# CCG2 register map
File version: 1.0
CPU: CM0 r1p0, little endian, no MPU, no FPU, 2 interrupt priority bits
Registers are 32-bit, read-write, reset 0x0 unless marked. A register's access mark holds for its fields unless they carry their own. Offsets are from the block's base; [hi:lo] are bit positions; {n}, {i} and the like mark numbered series; 'fields as' and 'values as' point back to an identical list.

## PERI
Base 0x40010000
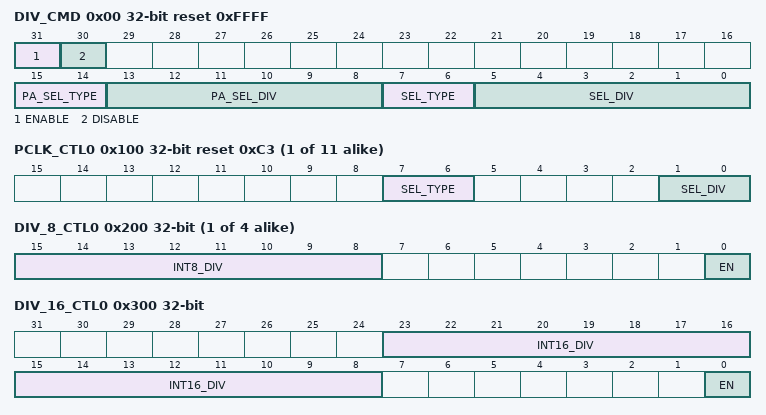
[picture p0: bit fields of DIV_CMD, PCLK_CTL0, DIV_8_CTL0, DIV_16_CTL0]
0x00 DIV_CMD reset 0xFFFF — Divider command register The (PA_SEL_TYPE, PA_SEL_DIV) field pair allows a divider to be phase aligned with another divider. E.g., consider a 48 MHz "clk_hf", and a need for a 12 MHz divided clock A and a 8 MHz divided clock B. Clock A uses 8.0 integer divider 0 and is created by aligning it to "clk_hf" ((PA_SEL_TYPE, PA_SEL_DIV) is (3, 63)) and DIV_8_CTL0.INT8_DIV is "4-1". Clock B uses 8.0 integer divider 1 and is created by aligning it to clock A ((PA_SEL_TYPE, PA_SEL_DIV) is (0, 0)) and DIV_8_CTL1.INT8_DIV is "6-1". This guarantees that clock B is phase aligned with clock B: as the smallest common multiple of the two clock periods is 12 "clk_hf" cycles, the clocks A and B will be aligned every 12 "clk_hf" cycles. Note: clock B is phase aligned to clock A, but still uses "clk_hf" as a reference clock for its divider value.
  [31] ENABLE — Clock divider enable command (mutually exclusive with DISABLE). Typically, SW sets this field to '1' to enable a divider and HW sets this field to '0' to indicate that divider enabling has completed. When a divider is enabled, its integer and fractional (if present) counters are initialized to "0". If a divider is to be re-enabled using different integer and fractional divider values, the SW should follow these steps: 0: Disable the divider using the DIV_CMD.DISABLE field. 1: Configure the divider's DIV_XXX_CTL register. 2: Enable the divider using the DIV_CMD_ENABLE field. The SEL_DIV and SEL_TYPE fields specify which divider is to be enabled. The enabled divider may be phase aligned to either "clk_hf" (typical usage) or to ANY enabled divider. The PA_SEL_DIV and P_SEL_TYPE fields specify the reference divider. The HW sets the ENABLE field to '0' when the enabling is performed and the HW set the DIV_XXX_CTL.EN field of the divider to '1' when the enabling is performed. Note that enabling with phase alignment to a low frequency divider takes time. E.g. To align to a divider that generates a clock of "clk_hf"/n (with n being the integer divider value INT_DIV+1), up to n cycles may be required to perform alignment. Phase alignment to "clk_hf" takes affect immediately. SW can set this field to '0' during phase alignment to abort the enabling process.
  [30] DISABLE — Clock divider disable command (mutually exlusive with ENABLE). SW sets this field to '1' and HW sets this field to '0'. The SEL_DIV and SEL_TYPE fields specify which divider is to be disabled. The HW sets the DISABLE field to '0' immediately and the HW sets the DIV_XXX_CTL.EN field of the divider to '0' immediately.
  [15:14] PA_SEL_TYPE — Specifies the divider type of the divider to which phase alignment is performed for the clock enable command: 0: 8.0 (integer) clock dividers. 1: 16.0 (integer) clock dividers. 2: 16.5 (fractional) clock dividers. 3: 24.5 (fractional) clock dividers.
  [13:8] PA_SEL_DIV — (PA_SEL_TYPE, PA_SEL_DIV) pecifies the divider to which phase alignment is performed for the clock enable command. Any enabled divider can be used as reference. This allows all dividers to be aligned with each other, even when they are enabled at different times. If PA_SEL_DIV is "63" and "PA_SEL_TYPE" is "3", "clk_hf" is used as reference.
  [7:6] SEL_TYPE — Specifies the divider type of the divider on which the command is performed: 0: 8.0 (integer) clock dividers. 1: 16.0 (integer) clock dividers. 2: 16.5 (fractional) clock dividers. 3: 24.5 (fractional) clock dividers.
  [5:0] SEL_DIV — (SEL_TYPE, SEL_DIV) specifies the divider on which the command (DISABLE/ENABLE) is performed. If SEL_DIV is "63" and "SEL_TYPE" is "3" (default/reset value), no divider is specified and no clock signal(s) are generated.
{0x100+4i} PCLK_CTL{i} reset 0xC3 (i=0..10) — Programmable clock control register
  [7:6] SEL_TYPE — Specifies divider type: 0: 8.0 (integer) clock dividers. 1: 16.0 (integer) clock dividers. 2: 16.5 (fractional) clock dividers. 3: 24.5 (fractional) clock dividers.
  [1:0] SEL_DIV — Specifies one of the dividers of the divider type specified by SEL_TYPE. If SEL_DIV is "63" and "SEL_TYPE" is "3" (default/reset value), no divider is specified and no clock control signal(s) are generated. When transitioning a clock between two out of phase dividers, spurious clock control signals may be generated for one �clk_hf� cycle during this transition. These clock control signals may cause a single clock period that is smaller than any of the two divider periods. To prevent these spurious clock signals, the clock multiplexer can be disconnected (SEL_DIV is "63" and "SEL_TYPE" is "3") for a transition time that is larger than the smaller of the two divider periods.
{0x200+4i} DIV_8_CTL{i} (i=0..3) — Divider control register (for 8.0 divider) Smallest of the divider types.
  [15:8] INT8_DIV — Integer division by (1+INT8_DIV). Allows for integer divisions in the range [1, 256]. Note: this type of divider does NOT allow for a fractional division. For the generation of a divided clock, the integer division range is restricted to [2, 256]. For the generation of a 50/50% duty cycle digital divided clock, the integer division range is resticited to even numbers in the range [2, 256]. The generation of a 50/50 % duty cycle analog divided clock has no restrictions. Note that this field is retained. However, the counter that is used to implement the division is not and will be initialized by HW to "0" when transitioning from DeepSleep to Active power mode.
  [0] EN ro — Divider enabled. HW sets this field to '1' as a result of an ENABLE command. HW sets this field to '0' as a result on a DISABLE command. Note that this field is retained. As a result, the divider does NOT have to be re-enabled after transitioning from DeepSleep to Active power mode.
0x300 DIV_16_CTL0 — Divider control register (for 16.0 divider)
  [23:8] INT16_DIV — Integer division by (1+INT16_DIV). Allows for integer divisions in the range [1, 65,536]. Note: this type of divider does NOT allow for a fractional division. For the generation of a divided clock, the integer division range is restricted to [2, 65,536]. For the generation of a 50/50% duty cycle digital divided clock, the integer division range is restricted to even numbers in the range [2, 65,536]. The generation of a 50/50 % duty cycle analog divided clock has no restrictions. Note that this field is retained. However, the counter that is used to implement the division is not and will be initialized by HW to "0" when transitioning from DeepSleep to Active power mode.
  [0] EN ro — Divider enabled. HW sets this field to '1' as a result of an ENABLE command. HW sets this field to '0' as a result on a DISABLE command. Note that this field is retained. As a result, the divider does NOT have to be re-enabled after transitioning from DeepSleep to Active power mode.
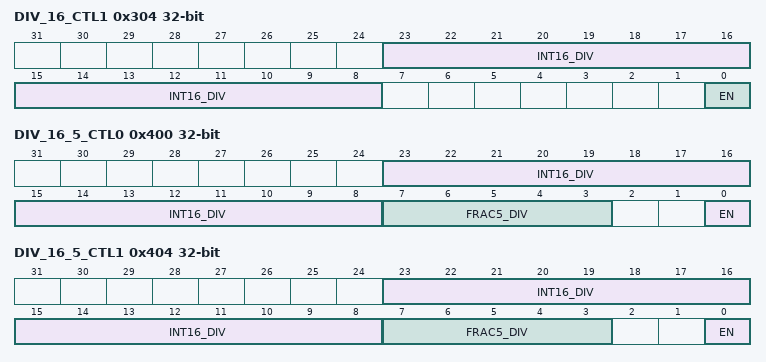
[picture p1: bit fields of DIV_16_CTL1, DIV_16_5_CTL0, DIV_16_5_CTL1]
0x304 DIV_16_CTL1 — Divider control register (for 16.0 divider)
  fields as DIV_16_CTL0
0x400 DIV_16_5_CTL0 — Divider control register (for 16.5 divider)
  [23:8] INT16_DIV — Integer division by (1+INT16_DIV). Allows for integer divisions in the range [1, 65,536]. Note: combined with fractional division, this divider type allows for a division in the range [1, 65,536 31/32] in 1/32 increments. For the generation of a divided clock, the division range is restricted to [2, 65,536 31/32]. For the generation of a 50/50% duty cycle divided clock, the division range is restricted to [2, 65,536]. Note that this field is retained. However, the counter that is used to implement the division is not and will be initialized by HW to "0" when transitioning from DeepSleep to Active power mode.
  [7:3] FRAC5_DIV — Fractional division by (FRAC5_DIV/32). Allows for fractional divisions in the range [0, 31/32]. Note that fractional division results in clock jitter as some clock periods may be 1 "clk_hf" cycle longer than other clock periods. Note that this field is retained. However, the counter that is used to implement the division is not and will be initialized by HW to "0" when transitioning from DeepSleep to Active power mode.
  [0] EN ro — Divider enabled. HW sets this field to '1' as a result of an ENABLE command. HW sets this field to '0' as a result on a DISABLE command. Note that this field is retained. As a result, the divider does NOT have to be re-enabled after transitioning from DeepSleep to Active power mode.
0x404 DIV_16_5_CTL1 — Divider control register (for 16.5 divider)
  fields as DIV_16_5_CTL0
